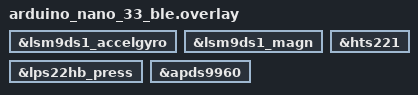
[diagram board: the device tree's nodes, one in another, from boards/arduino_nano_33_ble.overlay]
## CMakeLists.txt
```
cmake_minimum_required(VERSION 3.20.0)

set(CMAKE_CXX_STANDARD 17)
set(CMAKE_CXX_STANDARD_REQUIRED ON)

# EI model — export from EI Studio → Zephyr library, unzip next to this project
# so that ../model/CMakeLists.txt exists, then re-run `west build`.
if(EXISTS ${CMAKE_CURRENT_SOURCE_DIR}/../model/CMakeLists.txt)
    list(APPEND ZEPHYR_EXTRA_MODULES ${CMAKE_CURRENT_SOURCE_DIR}/../model)
    message(STATUS "EI model module: ${CMAKE_CURRENT_SOURCE_DIR}/../model")
else()
    message(STATUS "No EI model found — sensor streaming only (no local inference).")
endif()

find_package(Zephyr REQUIRED HINTS $ENV{ZEPHYR_BASE})
project(ei-zephyr-ble-gatt-client)

# Colorful diagnostics
zephyr_compile_options(-fdiagnostics-color=always)

# Avoid pulling in __cxa_guard_acquire/release (not provided by minimal C++ runtime)
zephyr_compile_options($<$<COMPILE_LANGUAGE:CXX>:-fno-threadsafe-statics>)

# Add include directories
target_include_directories(app PRIVATE
    src
    src/ble
    src/sensors
)

# Add application sources
target_sources(app PRIVATE
    src/main.cpp
    src/ble/gatt_client.cpp
    src/ble/gatt_server.cpp
    src/sensors/ei_sensor.cpp
)
```

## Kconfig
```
mainmenu "Edge Impulse BLE GATT Client"

config EI_SENSOR_LOCAL
	bool "Local sensor collection mode"
	depends on SENSOR
	default n
	help
	  When enabled the device reads on-board sensors directly instead of
	  acting as a BLE central that connects to an EI-Golioth peripheral.
	  Collected data is streamed over BLE GATT to an Android central, and
	  (optionally) fed into a locally-deployed EI impulse if a model/ is
	  present at build time.
	  Disabled by default; enabled automatically via boards/*.conf for
	  boards with on-board IMU (e.g. arduino_nano_33_ble).

config EI_SENSOR_SAMPLE_INTERVAL_MS
	int "Sensor sampling interval (ms)"
	depends on EI_SENSOR_LOCAL
	default 10
	range 1 1000
	help
	  How often to read the on-board sensors. Default is 10 ms (100 Hz).
	  Decrease for finer-resolution EI models; increase to save power.

source "Kconfig.zephyr"
```

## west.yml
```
manifest:

  remotes:
    - name: zephyrproject-rtos
      url-base: https://github.com/zephyrproject-rtos

  projects:
    - name: zephyr
      remote: zephyrproject-rtos
      repo-path: zephyr
      revision: main
      import: true

    - name: edge-impulse-sdk-zephyr
      description: Edge Impulse SDK for Zephyr
      path: modules/edge-impulse-sdk-zephyr
      west-commands: west/west-commands.yml
      revision: main
      url: https://github.com/edgeimpulse/edge-impulse-sdk-zephyr

  self:
    path: ei-zephyr-ble-gatt-client
```

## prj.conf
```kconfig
#----------------------- CORE -----------------------
CONFIG_SERIAL=y
CONFIG_CONSOLE=y
CONFIG_UART_CONSOLE=y
CONFIG_PRINTK=y

#----------------------- BLE CENTRAL + PERIPHERAL ----
CONFIG_BT=y
CONFIG_BT_CENTRAL=y
CONFIG_BT_PERIPHERAL=y
CONFIG_BT_GATT_CLIENT=y
CONFIG_BT_DEVICE_NAME="EI-Monitor"

# BLE scanning (uses Zephyr native bt_le_scan_start — no NCS BT_SCAN library needed)

# GATT client features
CONFIG_BT_GATT_AUTO_DISCOVER_CCC=y
CONFIG_BT_GATT_AUTO_SEC_REQ=n
CONFIG_BT_ATT_PREPARE_COUNT=2

# Connection parameters — need 2: one to EI-Golioth peripheral, one from Android central
CONFIG_BT_MAX_CONN=2
CONFIG_BT_BUF_ACL_RX_SIZE=255
CONFIG_BT_BUF_ACL_TX_SIZE=255
CONFIG_BT_L2CAP_TX_MTU=247

#----------------------- HEAP / MEMORY ---------------
CONFIG_HEAP_MEM_POOL_SIZE=65536
CONFIG_MAIN_STACK_SIZE=8192
CONFIG_SYSTEM_WORKQUEUE_STACK_SIZE=2048

#----------------------- LOCAL SENSOR (IMU) ----------
CONFIG_I2C=y
CONFIG_SENSOR=y
CONFIG_BMI270=y
CONFIG_EI_SENSOR_LOCAL=y

#----------------------- C++ ENABLED -----------------
CONFIG_CPP=y
CONFIG_STD_CPP17=y
CONFIG_NEWLIB_LIBC=y
CONFIG_NEWLIB_LIBC_FLOAT_PRINTF=y

#----------------------- LOGGING ---------------------
CONFIG_LOG=y
CONFIG_LOG_DEFAULT_LEVEL=3
CONFIG_BT_LOG_LEVEL_INF=y

#----------------------- STACK SIZE -------------------
CONFIG_MAIN_STACK_SIZE=16384
```

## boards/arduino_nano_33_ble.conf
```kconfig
# Arduino Nano 33 BLE Sense — board-specific Kconfig fragment.
# Picked up automatically by CMake when building for this board.

# I2C bus (all on-board sensors live on I2C0)
CONFIG_I2C=y
CONFIG_SENSOR=y

# LSM9DS1 — accel + gyro (I2C 0x6B)
CONFIG_LSM9DS1=y

# HTS221 — temperature + humidity (I2C 0x5F)
CONFIG_HTS221=y

# LPS22HB — barometric pressure (I2C 0x5C)
CONFIG_LPS22HB=y

# APDS9960 — proximity / colour / gesture (I2C 0x39)
CONFIG_APDS9960=y

# Enable local sensor collection mode (no BLE GATT client scanner)
CONFIG_EI_SENSOR_LOCAL=y

# More heap for sensor buffers + optional EI inference
CONFIG_HEAP_MEM_POOL_SIZE=65536
```

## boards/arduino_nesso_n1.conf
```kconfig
# Arduino Nesso N1 (ESP32-C6, RISC-V) — local-sensor mode
#
# On-board sensor: Bosch BMI270 6-axis IMU (bosch,bmi270) on I2C0.
# The BMI270 node is already declared and enabled in the upstream Zephyr
# board DTS, so no extra overlay nodes are needed.
#
# NOTE: The Arduino Nesso N1 was introduced in Zephyr after v4.0.0.
# If the build cannot find the board, update west.yml to a newer Zephyr
# revision (e.g. v4.1.0 or main) and re-run `west update`.

CONFIG_I2C=y
CONFIG_SENSOR=y
CONFIG_BMI270=y

CONFIG_EI_SENSOR_LOCAL=y

# ESP32-C6 needs more heap for BLE + sensor stack
CONFIG_HEAP_MEM_POOL_SIZE=65536

# ESP32-C6 binary blobs must be fetched once before building:
#   west blobs fetch hal_espressif
```

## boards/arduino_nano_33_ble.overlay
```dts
/*
 * Arduino Nano 33 BLE Sense — application board overlay.
 *
 * All on-board sensors are already declared in the Zephyr board DTS.
 * This overlay ensures they are active and sets parameters suitable
 * for Edge Impulse data collection.
 *
 * Sensors on the Arduino Nano 33 BLE Sense (nRF52840):
 *   LSM9DS1 @ 0x6B  — accelerometer + gyroscope   (compatible: st,lsm9ds1)
 *   LSM9DS1 @ 0x1E  — magnetometer                (compatible: st,lsm9ds1-magn)
 *   HTS221  @ 0x5F  — temperature + humidity       (compatible: st,hts221)
 *   LPS22HB @ 0x5C  — barometric pressure          (compatible: st,lps22hb-press)
 *   APDS9960 @ 0x39 — proximity / colour / gesture (compatible: avago,apds9960)
 */

/* Accelerometer + Gyroscope */
&lsm9ds1_accelgyro {
	status = "okay";
};

/* Magnetometer */
&lsm9ds1_magn {
	status = "okay";
};

/* Temperature + Humidity */
&hts221 {
	status = "okay";
};

/* Barometric Pressure */
&lps22hb_press {
	status = "okay";
};

/* Proximity / Colour / Gesture */
&apds9960 {
	status = "okay";
};
```

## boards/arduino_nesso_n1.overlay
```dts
/*
 * Arduino Nesso N1 — devicetree overlay
 *
 * The BMI270 6-axis IMU (bosch,bmi270) is already declared and enabled in the
 * upstream Zephyr board DTS for arduino_nesso_n1, so no extra nodes are needed.
 * This file is kept as a placeholder for future additions (e.g. pin-mux
 * adjustments or additional peripheral enables).
 */
```

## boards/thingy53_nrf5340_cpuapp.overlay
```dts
/*
 * Copyright (c) 2025 EdgeImpulse Inc.
 * SPDX-License-Identifier: BSD-3-Clause
 */

/ {
    chosen {
        zephyr,console = &uart0;
        zephyr,shell-uart = &uart0;
    };
};

/* Ensure UART is enabled for serial output */
&uart0 {
    status = "okay";
    current-speed = <115200>;
};
```

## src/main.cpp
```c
/* The Clear BSD License
 *
 * Copyright (c) 2025 EdgeImpulse Inc.
 * All rights reserved.
 *
 * SPDX-License-Identifier: BSD-3-Clause
 */

#include <zephyr/kernel.h>
#include <zephyr/logging/log.h>
#include "ble/gatt_client.h"
#include "ble/gatt_server.h"
#include "sensors/ei_sensor.h"

LOG_MODULE_REGISTER(main, LOG_LEVEL_INF);

// Connection state
static bool is_connected = false;

/**
 * @brief Handle inference result from BLE peripheral
 */
static void on_inference_received(const inference_result_t *result)
{
    printk("\n=== Inference Result ===\n");
    printk("Label: %s\n", result->label);
    printk("Confidence: %.1f%%\n", result->confidence * 100.0f);
    printk("DSP Time: %u ms\n", result->dsp_time_ms);
    printk("Classification Time: %u ms\n", result->classification_time_ms);
    printk("Total Time: %u ms\n", result->dsp_time_ms + result->classification_time_ms);
    printk("========================\n\n");

    /* Relay result to any connected Android central */
    gatt_server_notify_inference(result);
}

/**
 * @brief Handle connection state changes
 */
static void on_connection_changed(bool connected)
{
    is_connected = connected;

    if (connected) {
        printk("\n>>> Connected to EI-Golioth device!\n");
        
        // Small delay then enable notifications
        k_sleep(K_MSEC(500));
        gatt_client_enable_inference_notifications();
    } else {
        printk("\n>>> Disconnected from device\n");
        printk(">>> Rescanning in 2 seconds...\n\n");
        
        // Restart scanning
        k_sleep(K_SECONDS(2));
        gatt_client_start_scan();
    }
}

/**
 * @brief Handle sensor data from BLE peripheral
 */
static void on_sensor_data_received(const float *data, size_t len)
{
    LOG_DBG("Sensor data received: %zu samples", len);
    /* Relay raw sensor samples to any connected Android central */
    gatt_server_notify_sensor_data(data, len);
}

int main(void)
{
    printk("\n");
    printk("========================================\n");
    printk("  Edge Impulse BLE GATT Client\n");

#ifdef CONFIG_EI_SENSOR_LOCAL
    printk("  Mode: Local Sensor Collection\n");
    printk("  Board: %s\n", CONFIG_BOARD);
#else
    printk("  Mode: BLE Relay (EI-Golioth Monitor)\n");
#endif

    printk("========================================\n\n");

    /*
     * gatt_client_init() calls bt_enable() which is needed in both modes.
     * In local-sensor mode we skip start_scan() and drive the sensor loop
     * instead.
     */
    int err = gatt_client_init();
    if (err) {
        printk("ERROR: BLE init failed: %d\n", err);
        return err;
    }

    /* Start the GATT server so Android can connect and receive data */
    err = gatt_server_init();
    if (err) {
        printk("WARNING: GATT server init failed: %d (continuing)\n", err);
    }

#ifdef CONFIG_EI_SENSOR_LOCAL
    /*
     * Local sensor mode — Arduino Nano 33 BLE Sense (or any board with
     * an on-board IMU declared in the devicetree).
     *
     * Sensors sampled at CONFIG_EI_SENSOR_SAMPLE_INTERVAL_MS (default 10 ms
     * = 100 Hz). Raw data is streamed to Android; if an EI model is present
     * at build time inference results are also notified.
     */
    err = ei_sensor_init();
    if (err) {
        printk("ERROR: Sensor init failed: %d\n", err);
        return err;
    }

    printk("Starting local sensor collection (sampling every %d ms)...\n\n",
           CONFIG_EI_SENSOR_SAMPLE_INTERVAL_MS);

    /* Does not return */
    ei_sensor_run_loop();

#else
    /*
     * Relay mode — Thingy:53 (or any board without on-board IMU).
     *
     * Scans for an "EI-Golioth" BLE peripheral, subscribes to inference
     * and sensor notifications, then re-advertises them to an Android central
     * via the GATT server.
     */
    gatt_client_register_inference_callback(on_inference_received);
    gatt_client_register_connection_callback(on_connection_changed);
    gatt_client_register_sensor_callback(on_sensor_data_received);

    printk("Scanning for EI-Golioth devices...\n\n");
    err = gatt_client_start_scan();
    if (err) {
        printk("ERROR: Failed to start scan: %d\n", err);
        return err;
    }

    while (1) {
        k_sleep(K_SECONDS(1));
    }
#endif

    return 0;
}
```
